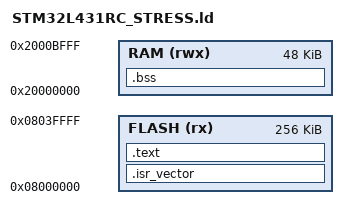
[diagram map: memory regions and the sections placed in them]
/* STM32L431RC: 256 KB flash, 48 KB SRAM1 (stack at its top) */
MEMORY
{
    FLASH (rx)  : ORIGIN = 0x08000000, LENGTH = 256K
    RAM   (rwx) : ORIGIN = 0x20000000, LENGTH = 48K
}

_estack = ORIGIN(RAM) + LENGTH(RAM);

SECTIONS
{
    .isr_vector : { KEEP(*(.isr_vector)) } > FLASH
    .text       : { *(.text*) *(.rodata*) } > FLASH
    .bss (NOLOAD) : { *(.bss*) *(COMMON) } > RAM
}
